# NSUC1602 register map
Vendor: ARM Ltd.; Series: NSUC1602; File version: 0.0
ARM 32-bit Cortex-M3 Microcontroller based device, CPU clock up to 48MHz, etc.
CPU: CM3 r1p0, little endian, MPU, no FPU, 3 interrupt priority bits
Registers are 32-bit, read-write, reset 0x0 unless marked. A register's access mark holds for its fields unless they carry their own. Offsets are from the block's base; lines under a group give offsets from that group; [hi:lo] are bit positions; {n}, {i} and the like mark numbered series; 'fields as' and 'values as' point back to an identical list; <NAME> marks a mode.

## Memory map
0x40000000 GDU size 0x100 — S/T bus
0x40001000 SPI size 0x100 — S/T bus
0x40002000 LINPORT size 0x100 — S/T bus
0x40003000 LINUART size 0x100 — S/T bus
0x40004000 PWMIO size 0x100 — S/T bus
0x40005000 TIM0 size 0x100 — S/T bus
0x40006000 TIM1 size 0x100 — S/T bus
0x40007000 WWDG size 0x100 — S/T bus
0x40008000 DWDG size 0x100 — S/T bus
0x40009000 UART1 size 0x100 — S/T bus
0x4000A000 SSI size 0x100 — S/T bus
0x40020000 SYSCTRL size 0x100 — S/T bus
0x40021000 EPWM size 0x100 — S/T bus
0x40022000 ADC size 0x100 — S/T bus
0x40024000 APMU size 0x100 — S/T bus
0x40025000 GPIO size 0x100 — S/T bus
0x40030000 FLASHCTRL size 0x100 — S/T bus

## FLASHCTRL — S/T bus
Base 0x40030000
0x00 RDCR — FLASH读取控制寄存器
  [1:0] WAIT
0x04 PFCR — 预取指控制寄存器
  [0] PFTPHS_EN
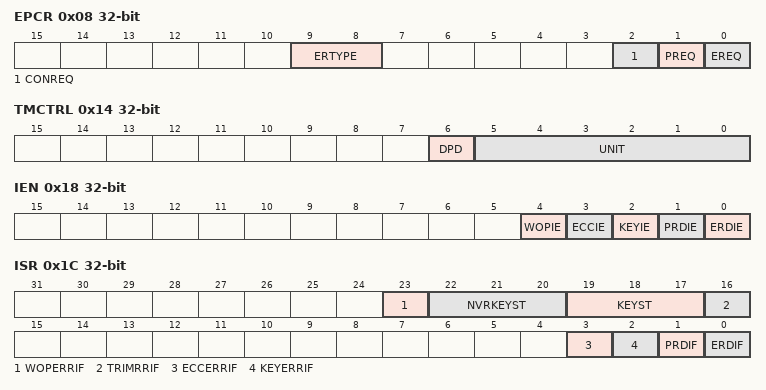
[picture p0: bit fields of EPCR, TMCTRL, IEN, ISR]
0x08 EPCR — Flash 擦写控制寄存器
  [9:8] ERTYPE, [2] CONREQ, [1] PREQ, [0] EREQ
0x0C KEY (reset mask 0x1337F7F) — Flash Key 输入寄存器
  [31:0] FLS_KEY
0x10 NVRKEY (reset mask 0x1337F7F) — Flash NVR Key 输入寄存器
  [31:0] FLS_NVRKEY
0x14 TMCTRL — Flash Timing 控制寄存器
  [6] DPD, [5:0] UNIT
0x18 IEN — Flash 中断使能寄存器
  [4] WOPIE, [3] ECCIE, [2] KEYIE, [1] PRDIE, [0] ERDIE
0x1C ISR (reset mask 0x1337F7F) — Flash 标志寄存器
  [23] WOPERRIF, [22:20] NVRKEYST, [19:17] KEYST, [16] TRIMRRIF, [3] ECCERRIF, [2] KEYERRIF, [1] PRDIF, [0] ERDIF

## SYSCTRL — S/T bus
Base 0x40020000
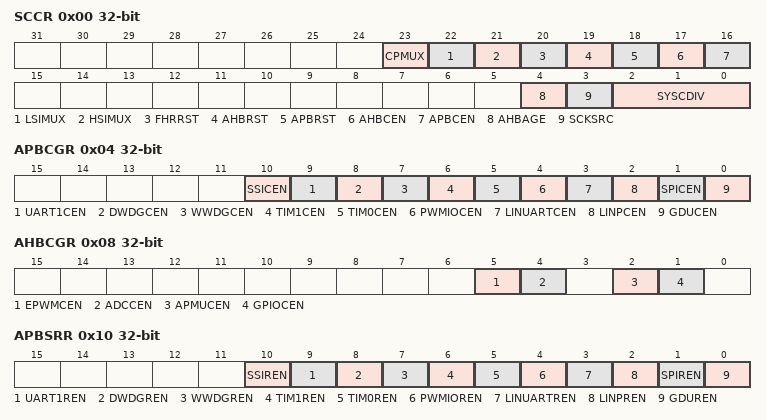
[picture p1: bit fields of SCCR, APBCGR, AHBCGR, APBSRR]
0x00 SCCR (reset mask 0x1337F7F) — 系统时钟控制寄存器
  [23] CPMUX, [22] LSIMUX, [21] HSIMUX, [20] FHRRST, [19] AHBRST, [18] APBRST, [17] AHBCEN, [16] APBCEN, [4] AHBAGE, [3] SCKSRC, [2:0] SYSCDIV
0x04 APBCGR (reset mask 0x1337F7F) — APB时钟门控寄存器
  [10] SSICEN, [9] UART1CEN, [8] DWDGCEN, [7] WWDGCEN, [6] TIM1CEN, [5] TIM0CEN, [4] PWMIOCEN, [3] LINUARTCEN, [2] LINPCEN, [1] SPICEN, [0] GDUCEN
0x08 AHBCGR — AHB时钟门控寄存器
  [5] EPWMCEN, [4] ADCCEN, [2] APMUCEN, [1] GPIOCEN
0x10 APBSRR (reset mask 0x1337F7F) — APB软复位寄存器
  [10] SSIREN, [9] UART1REN, [8] DWDGREN, [7] WWDGREN, [6] TIM1REN, [5] TIM0REN, [4] PWMIOREN, [3] LINUARTREN, [2] LINPREN, [1] SPIREN, [0] GDUREN
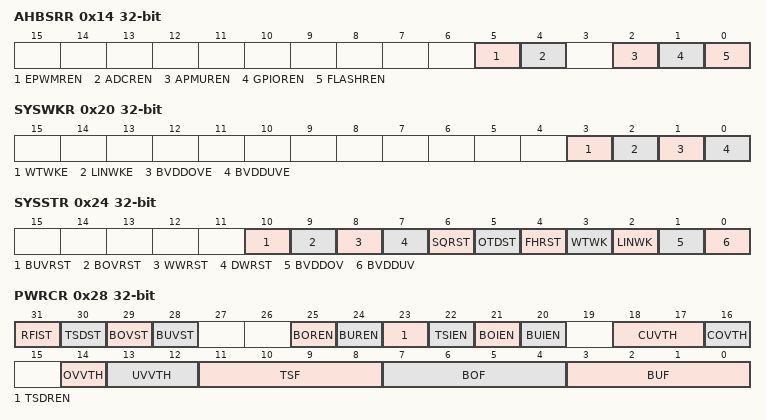
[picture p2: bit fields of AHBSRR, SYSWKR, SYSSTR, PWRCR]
0x14 AHBSRR — AHB软复位寄存器
  [5] EPWMREN, [4] ADCREN, [2] APMUREN, [1] GPIOREN, [0] FLASHREN
0x20 SYSWKR — 系统唤醒寄存器
  [3] WTWKE, [2] LINWKE, [1] BVDDOVE, [0] BVDDUVE
0x24 SYSSTR (reset mask 0x1337F7F) — 系统状态寄存器
  [10] BUVRST, [9] BOVRST, [8] WWRST, [7] DWRST, [6] SQRST, [5] OTDST, [4] FHRST, [3] WTWK, [2] LINWK, [1] BVDDOV, [0] BVDDUV
0x28 PWRCR (reset mask 0x1337F7F) — 电源控制寄存器
  [31] RFIST, [30] TSDST, [29] BOVST, [28] BUVST, [25] BOREN, [24] BUREN, [23] TSDREN, [22] TSIEN, [21] BOIEN, [20] BUIEN, [18:17] CUVTH, [16] COVTH, [14] OVVTH, [13:12] UVVTH, [11:8] TSF, [7:4] BOF, [3:0] BUF
0x2C APMUSTR — APMU Status状态寄存器
  [5:0] STAR
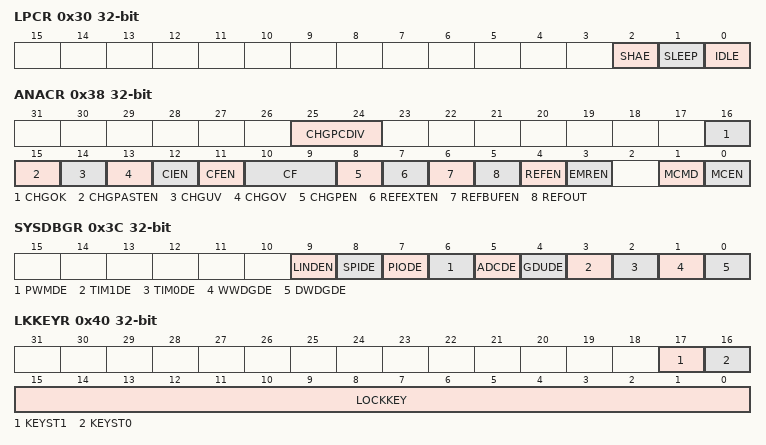
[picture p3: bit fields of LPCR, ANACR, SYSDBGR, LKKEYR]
0x30 LPCR — 低功耗控制寄存器
  [2] SHAE, [1] SLEEP, [0] IDLE
0x38 ANACR (reset mask 0x1337F7F) — 模拟配置寄存器
  [25:24] CHGPCDIV, [16] CHGOK, [15] CHGPASTEN, [14] CHGUV, [13] CHGOV, [12] CIEN, [11] CFEN, [10:9] CF, [8] CHGPEN, [7] REFEXTEN, [6] REFBUFEN, [5] REFOUT, [4] REFEN, [3] EMREN, [1] MCMD, [0] MCEN
0x3C SYSDBGR (reset mask 0x1337F7F) — 系统调试寄存器
  [9] LINDEN, [8] SPIDE, [7] PIODE, [6] PWMDE, [5] ADCDE, [4] GDUDE, [3] TIM1DE, [2] TIM0DE, [1] WWDGDE, [0] DWDGDE
0x40 LKKEYR (reset mask 0x1337F7F) — 锁键寄存器
  [17] KEYST1, [16] KEYST0, [15:0] LOCKKEY
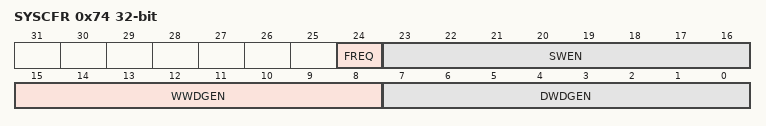
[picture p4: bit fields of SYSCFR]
0x74 SYSCFR (reset mask 0x1337F7F) — 系统控制配置寄存器
  [24] FREQ, [23:16] SWEN ro, [15:8] WWDGEN, [7:0] DWDGEN
0xA8 GDUTRIM — gdutrim 寄存器
  [3:0] GDUTRIMSHAE ro
0xAC ADCTRIM (reset mask 0x1337F7F) — adctrim 寄存器
  [30:0] ADCTRIMSHAE ro
0xB0 TEMPTRIM (reset mask 0x1337F7F) — temptrim 寄存器
  [23:0] TEMPTRIMSHAE ro

## Licence text in the file
ARM Limited (ARM) is supplying this software for use with Cortex-M processor based microcontroller, but can be equally used for other suitable processor architectures. This file can be freely distributed. Modifications to this file shall be clearly marked. . THIS SOFTWARE IS PROVIDED "AS IS". NO WARRANTIES, WHETHER EXPRESS, IMPLIED. OR STATUTORY, INCLUDING, BUT NOT LIMITED TO, IMPLIED WARRANTIES OF. MERCHANTABILITY AND FITNESS FOR A PARTICULAR PURPOSE APPLY TO THIS SOFTWARE. ARM SHALL NOT, IN ANY CIRCUMSTANCES, BE LIABLE FOR SPECIAL, INCIDENTAL, OR. CONSEQUENTIAL DAMAGES, FOR ANY REASON WHATSOEVER.

## Notices in the file
Copyright (C) 2013-2022 NOVOSNS Limited. All rights reserved.
Purpose: System Viewer Description (SVD) Example (Schema Version 1.1)
This is a description of a none-existent and incomplete device
for demonstration purposes only.
Redistribution and use in source and binary forms, with or without
modification, are permitted provided that the following conditions are met:
- Redistributions of source code must retain the above copyright
notice, this list of conditions and the following disclaimer.
- Redistributions in binary form must reproduce the above copyright
notice, this list of conditions and the following disclaimer in the
documentation and/or other materials provided with the distribution.
- Neither the name of ARM nor the names of its contributors may be used
to endorse or promote products derived from this software without
specific prior written permission.
THIS SOFTWARE IS PROVIDED BY THE COPYRIGHT HOLDERS AND CONTRIBUTORS "AS IS"
AND ANY EXPRESS OR IMPLIED WARRANTIES, INCLUDING, BUT NOT LIMITED TO, THE
ARE DISCLAIMED. IN NO EVENT SHALL COPYRIGHT HOLDERS AND CONTRIBUTORS BE
LIABLE FOR ANY DIRECT, INDIRECT, INCIDENTAL, SPECIAL, EXEMPLARY, OR
CONSEQUENTIAL DAMAGES (INCLUDING, BUT NOT LIMITED TO, PROCUREMENT OF
SUBSTITUTE GOODS OR SERVICES; LOSS OF USE, DATA, OR PROFITS; OR BUSINESS
INTERRUPTION) HOWEVER CAUSED AND ON ANY THEORY OF LIABILITY, WHETHER IN
CONTRACT, STRICT LIABILITY, OR TORT (INCLUDING NEGLIGENCE OR OTHERWISE)
ARISING IN ANY WAY OUT OF THE USE OF THIS SOFTWARE, EVEN IF ADVISED OF THE
POSSIBILITY OF SUCH DAMAGE.
